# uart_revc register map
Registers are 32-bit, access not given, no defined reset value unless marked. A register's access mark holds for its fields unless they carry their own. Offsets are from the block's base; lines under a group give offsets from that group; [hi:lo] are bit positions; {n}, {i} and the like mark numbered series; 'fields as' and 'values as' point back to an identical list; <NAME> marks a mode.

## Memory map
0x40020000 UART0 size 0x1000 — UART

## Interrupts
14 UART0 — UART0 IRQ

## UART0 — UART
Base 0x40020000
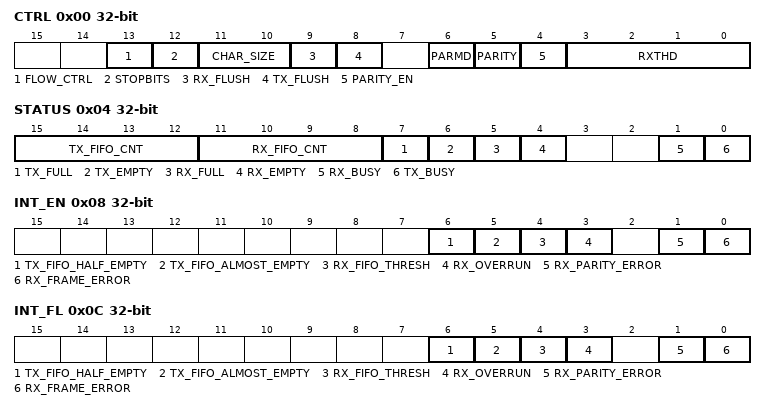
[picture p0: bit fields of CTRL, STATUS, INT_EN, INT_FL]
0x00 CTRL — Control Register.
  [13] FLOW_CTRL — Enables/disables hardware flow control.
    1=en (HW Flow Control with RTS/CTS enabled); 0=dis (HW Flow Control disabled)
  [12] STOPBITS — Selects the number of stop bits that will be generated.
    0=1 stop bit; 1=1_5 (1.5 stop bits.)
  [11:10] CHAR_SIZE — Selects UART character size.
    {v}={v+5} bits (v=0..3)
  [9] RX_FLUSH — Flushes the RX FIFO buffer.
  [8] TX_FLUSH — Flushes the TX FIFO buffer.
  [6] PARMD — Selects parity based on 1s or 0s count (when PARITY_EN=1).
    0=Parity calculation is based on number of 1s in frame; 1=Parity calculation is based on number of 0s in frame
  [5] PARITY — When PARITY_EN=1, selects odd or even parity.
    0=Even parity selected; 1=ODD (Odd parity selected.)
  [4] PARITY_EN — Enable/disable Parity bit (9th character).
    0=dis (No Parity); 1=en (Parity enabled as 9th bit)
  [3:0] RXTHD — Receive Threshhold.
0x04 STATUS ro
  [15:12] TX_FIFO_CNT — Indicates the number of bytes currently in the TX FIFO.
  [11:8] RX_FIFO_CNT — Indicates the number of bytes currently in the RX FIFO.
  [7] TX_FULL — Read-only flag indicating the TX FIFO state.
  [6] TX_EMPTY — Read-only flag indicating the TX FIFO state.
  [5] RX_FULL — Read-only flag indicating the RX FIFO state.
  [4] RX_EMPTY — Read-only flag indicating the RX FIFO state.
  [1] RX_BUSY — Read-only flag indicating the UART receiver status.
  [0] TX_BUSY — Read-only flag indicating the UART transmit status.
0x08 INT_EN — Interrupt Enable Register.
  [6] TX_FIFO_HALF_EMPTY — Enable for interrupt when TX FIFO reaches half the number of bytes allowed in the fifo or less.
  [5] TX_FIFO_ALMOST_EMPTY — Enable for interrupt when TX FIFO has only one byte remaining.
  [4] RX_FIFO_THRESH — Enable for interrupt when RX FIFO reaches the number of bytes configured by the RXTHD field.
  [3] RX_OVERRUN — Enable for RX FIFO OVerrun interrupt.
  [1] RX_PARITY_ERROR — Enable for RX Parity Error interrupt.
  [0] RX_FRAME_ERROR — Enable for RX Frame Error Interrupt.
0x0C INT_FL write-1-clears — Interrupt Status Flags.
  [6] TX_FIFO_HALF_EMPTY — FLAG for interrupt when TX FIFO reaches half the number of bytes allowed in the fifo or less.
  [5] TX_FIFO_ALMOST_EMPTY — FLAG for interrupt when TX FIFO has only one byte remaining.
  [4] RX_FIFO_THRESH — FLAG for interrupt when RX FIFO reaches the number of bytes configured by the RXTHD field.
  [3] RX_OVERRUN — FLAG for RX FIFO Overrun interrupt.
  [1] RX_PARITY_ERROR — FLAG for RX Parity Error interrupt.
  [0] RX_FRAME_ERROR — FLAG for RX Frame Error Interrupt.
0x10 BAUD0 — Baud rate register. Integer portion.
  [11:0] IBAUD — Integer portion of baud rate divisor value. IBAUD = InputClock / (factor * Baud Rate Frequency).
0x14 BAUD1 — Baud rate register. Decimal Setting.
  [6:0] DBAUD — Decimal portion of baud rate divisor value. DIV = InputClock/(factor*Baud Rate Frequency). DDIV=(DIV-IDIV)*128.
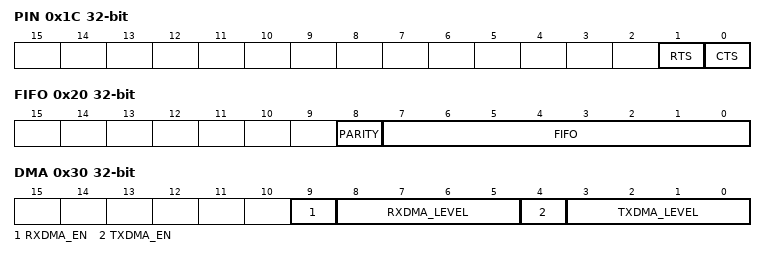
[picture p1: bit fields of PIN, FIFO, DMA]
0x1C PIN — UART Pin Control Register.
  [1] RTS — If hardware flow control is disabled, this bit may be used to control RTS output.
  [0] CTS — Current state of CTS pin.
0x20 FIFO — FIFO Data buffer.
  [8] PARITY — Parity error flag for next byte to be read from FIFO.
  [7:0] FIFO — Load/unload location for TX and RX FIFO buffers.
0x30 DMA — DMA Configuration.
  [9] RXDMA_EN — RX DMA channel enable.
    0=dis (DMA is disabled); 1=en (DMA is enabled)
  [8:5] RXDMA_LEVEL — RX threshold for DMA transmission.
  [4] TXDMA_EN — TX DMA channel enable.
    0=dis (DMA is disabled); 1=en (DMA is enabled)
  [3:0] TXDMA_LEVEL — TX threshold for DMA transmission.
